# MINI51AN_v1 register map
File version: 1.0
Registers are 32-bit, read-write, reset 0x0 unless marked. A register's access mark holds for its fields unless they carry their own. Offsets are from the block's base; [hi:lo] are bit positions; 'fields as' and 'values as' point back to an identical list.

## CLK — CLK Register Map
Base 0x50000200
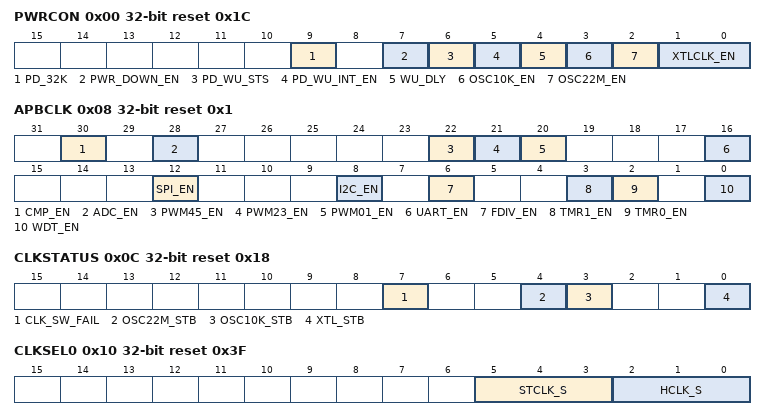
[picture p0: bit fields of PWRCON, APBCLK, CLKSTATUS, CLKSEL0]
0x00 PWRCON reset 0x1C — System Power-down Control Register
  [9] PD_32K — This bit controls the crystal oscillator active or not in Power-down mode.
    0=No effect to Power-down mode; 1=If XTLCLK_EN[1:0] = 10, LXT is still active in Power-down mode
  [7] PWR_DOWN_EN — System Power-down Active or Enable Bit. When chip waked up from power-down, this bit is automatically cleared, and user needs to set this bit again for the next power-down. In Power-down mode, the LDO, external crystal and the HIRC will be disabled, and the LIRC enable is not controlled by this bit.
    0=Chip operated in Normal mode or CPU enters into Idle mode; 1=Chip entering the Power-down mode instantly or wait CPU Idle command
  [6] PD_WU_STS — Power-down Mode Wake-up Interrupt Status. When set by "power-down wake-up event", it indicates that resume from Power-down mode. The flag is set if the GPIO, UART, WDT, ACMP, Timer or BOD wake-up occurred. Software can write 1 to clear the bit to zero. Note: This bit is working only if PD_WU_INT_EN (PWRCON[5]) is set to 1.
  [5] PD_WU_INT_EN — Power-down Mode Wake-up Interrupt Enable (Write-protected). The interrupt will occur when both PD_WU_STS and PD_WU_INT_EN are high.
    0=Disabled; 1=Enabled. The interrupt will occur when Power-down mode wake up
  [4] WU_DLY — Wake-up Delay Counter Enable (Write-protected). When the chip wakes up from Power-down mode, the clock control will delay certain clock cycles to wait system clock stable. The delayed clock cycle is 4096 clock cycles when chip work at HXT, 4096 clock cycle for LXT, and 16 clock cycles when chip work at HIRC oscillator.
    0=Clock cycles delay Disabled; 1=Clock cycles delay Enabled
  [3] OSC10K_EN — LIRC Control
    0=LIRC oscillator Disabled; 1=LIRC oscillator Enabled
  [2] OSC22M_EN — HIRC Control. Note: The default of OSC22M_EN bit is 1.
    0=HIRC oscillator Disabled; 1=HIRC oscillator Enabled
  [1:0] XTLCLK_EN — External HXT or LXT Crystal Oscillator Control. The default clock source is from HIRC. These two bits are default set to "00" and the XTAL1 and XTAL2 pins are GPIO. Note: To enable external XTAL function, P5_ALT[1:0] and P5_MFP[1:0] bits must also be set in P5_MFP.
    0=XTAL1 and XTAL2 are GPIO, disable both LXT HXT (default); 1=HXT Enabled; 2=LXT Enabled; 3=XTAL1 is external clock input pin, XTAL2 is GPIO
0x04 AHBCLK reset 0x5 — AHB Device Clock Enable Control Register
  [2] ISP_EN — Flash ISP Controller Clock Enable Control
    0=Flash ISP engine clock Disabled; 1=Flash ISP engine clock Enabled
0x08 APBCLK reset 0x1 — APB Device Clock Enable Control Register
  [30] CMP_EN — Comparator Clock Enable
    0=Analog Comparator Clock Disabled; 1=Analog Comparator Clock Enabled
  [28] ADC_EN — Analog-Digital-Converter (ADC) Clock Enable Control
    0=Both the ADC's APB and the engine clock Disabled; 1=Both the ADC's APB and the engine clock Enabled
  [22] PWM45_EN — PWM_45 Clock Enable Control
    0=Both the PWM45 APB and the engine clock Disabled; 1=Both the PWM45 APB and the engine clock Enabled
  [21] PWM23_EN — PWM_23 Clock Enable Control
    0=Both the PWM23 APB and the engine clock Disabled; 1=Both the PWM23 APB and the engine clock Enabled
  [20] PWM01_EN — PWM_01 Clock Enable Control
    0=Both the PWM01 APB and the engine clock Disabled; 1=Both the PWM01 APB and the engine clock Enabled
  [16] UART_EN — UART Clock Enable Control
    0=Both the UART APB and the engine clock Disabled; 1=Both the UART APB and the engine clock Enabled
  [12] SPI_EN — SPI Clock Enable Control
    0=Disabled; 1=Enabled
  [8] I2C_EN — I2C Clock Enable Control
    0=Disabled; 1=Enabled
  [6] FDIV_EN — Clock Divider Clock Enable Control
    0=Disabled; 1=Enabled
  [3] TMR1_EN — Timer1 Clock Enable Control
    0=Disabled; 1=Enabled
  [2] TMR0_EN — Timer0 Clock Enable Control
    0=Disabled; 1=Enabled
  [0] WDT_EN — Watchdog Clock Enable. This bit is the protected bit; programming this needs an open lock sequence, write 0x59, 0x16, 0x88 to address 0x5000_0100 to un-lock this bit. Refer to the register RegLockAddr at address GCR_BA + 0x100.
    0=Disabled; 1=Enabled
0x0C CLKSTATUS reset 0x18 — Clock Status Monitor Register
  [7] CLK_SW_FAIL — Clock Switch Fail Flag. This bit will be set when target switch clock source is not stable. Software can write 1 to clear this bit to zero.
    0=Clock switch success; 1=Clock switch failed
  [4] OSC22M_STB — HIRC Clock Source Stable Flag
    0=HIRC clock not stable or not enabled; 1=HIRC clock stable
  [3] OSC10K_STB — LIRC Clock Source Stable Flag
    0=LIRC clock not stable or not enabled; 1=LIRC clock stable
  [0] XTL_STB — HXT or LXT Clock Source Stable Flag
    0=HXT or LXT clock not stable or not enabled; 1=HXT or LXT clock stable
0x10 CLKSEL0 reset 0x3F — Clock Source Select Control Register 0
  [5:3] STCLK_S — Cortex-M0 CPU SysTick Clock Source Selection. Note: To set PWRCON[1:0], select HXT or LXT crystal clock.
    0=Clock source from HXT or LXT crystal clock; 2=Clock source from HXT or LXT crystal clock/2; 3=Clock source from HCLK/2; 7=Clock source from HIRC oscillator clock/2
  [2:0] HCLK_S — HCLK Clock Source Selection. Note: Before clock switch the related clock sources (pre-select and new-select) must be turned on. These bits are protected bit; programming this needs an open lock sequence, write 0x59, 0x16, 0x88 to address 0x5000_0100 to un-lock this bit. Refer to the register RegLockAddr at address GCR_BA + 0x100. Note: To set PWRCON[1:0] to select HXT or LXT crystal clock.
    0=Clock source from HXT or LXT crystal clock; 3=Clock source from LIRC oscillator clock; 7=Clock source from HIRC oscillator clock
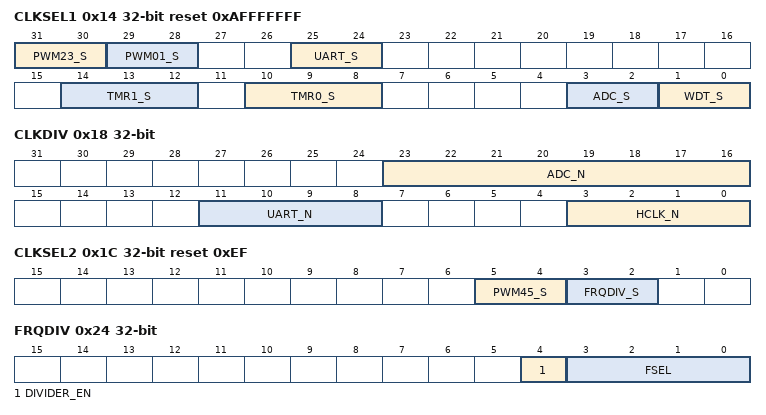
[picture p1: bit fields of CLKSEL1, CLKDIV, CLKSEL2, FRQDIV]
0x14 CLKSEL1 reset 0xAFFFFFFF — Clock Source Select Control Register 1
  [31:30] PWM23_S — PWM2 and PWM3 Clock Source Selection. PWM2 and PWM3 use the same Engine clock source. They both have the same pre-scalar. Note: To set PWRCON[1:0], select HXT or LXT crystal clock.
    2=Clock source from HCLK
  [29:28] PWM01_S — PWM0 and PWM1 Clock Source Selection. PWM0 and PWM1 use the same Engine clock source. They both have the same pre-scalar. Note: To set PWRCON[1:0], select HXT or LXT crystal clock.
    2=Clock source from HCLK
  [25:24] UART_S — UART Clock Source Selection. Note: To set PWRCON[1:0], select HXT or LXT crystal clock.
    0=Clock source from HXT or LXT crystal clock; 2=Clock source from HIRC oscillator clock
  [14:12] TMR1_S — TIMER1 Clock Source Selection. Note: To set PWRCON[1:0], select HXT or LXT crystal clock.
    0=Clock source from HXT or LXT crystal clock; 1=Clock source from LIRC oscillator clock; 2=Clock source from HCLK; 3=Clock source from external trigger; 7=Clock source from HIRC oscillator clock
  [10:8] TMR0_S — TIMER0 Clock Source Selection. Note: To set PWRCON[1:0], select HXT or LXT crystal clock.
    values as TMR1_S
  [3:2] ADC_S — ADC Clock Source Selection. Note: To set PWRCON[1:0], select HXT or LXT crystal clock.
    0=Clock source from HXT or LXT crystal clock; 2=Clock source from HCLK clock; 3=Clock source from HIRC oscillator clock
  [1:0] WDT_S — WDT CLK Clock Source Selection. These bits are protected bit, programming this needs an open lock sequence, write 0x59, 0x16, 0x88 to address 0x5000_0100 to un-lock this bit. Refer to the register RegLockAddr at address GCR_BA + 0x100. Note: To set PWRCON[1:0], select HXT or LXT crystal clock.
    0=Clock source from HXT or LXT crystal clock; 2=Clock source from HCLK/2048 clock; 3=Clock source from LIRC oscillator clock
0x18 CLKDIV — Clock Divider Number Register
  [23:16] ADC_N — ADC Clock Divide Number from ADC Clock Source
  [11:8] UART_N — UART Clock Divide Number from UART Clock Source
  [3:0] HCLK_N — HCLK Clock Divide Number from HCLK Clock Source
0x1C CLKSEL2 reset 0xEF — Clock Source Select Control Register 2
  [5:4] PWM45_S — PWM4 and PWM5 Clock Source Selection - PWM4 and PWM5 use the same Engine clock source. They both have the same pre-scalar. Note: To set PWRCON[1:0], select HXT or LXT crystal clock.
    2=Clock source from HCLK
  [3:2] FRQDIV_S — Clock Divider Clock Source Selection. Note: To set PWRCON[1:0], select HXT or LXT crystal clock.
    0=Clock source from HXT or LXT crystal clock; 2=Clock source from HCLK; 3=Clock source from HIRC oscillator clock
0x24 FRQDIV — Frequency Divider Control Register
  [4] DIVIDER_EN — Frequency Divider Enable Bit
    0=Frequency Divider Disabled; 1=Frequency Divider Enabled
  [3:0] FSEL — Divider Output Frequency Selection Bits. The formula of output frequency is. Fin is the input clock frequency. Fout is the frequency of divider output clock. N is the 4-bit value of FSEL[3:0].
